# ESP32S31_RADIO register map
Vendor: Espressif; Series: ESP32-S31; File version: 3.52
Registers are 32-bit, read-write, no defined reset value unless marked. A register's access mark holds for its fields unless they carry their own. Offsets are from the block's base; [hi:lo] are bit positions; {n}, {i} and the like mark numbered series; <NAME> marks a mode.

## BLUETOOTH_SCHEDULER_INTERRUPT_RUNTIME — Two scheduler words transferred with BLUETOOTH_INTERRUPT_BANK to the primary hard handler. The complete source-124 suffix can read SCHEDULER_STATE at two distinct temporal points and can write a complete zero image to SCHEDULER_REFERENCE. Keeping this sparse physical view outside the task-side controller partition prevents either owner from manufacturing an MMIO alias.
Base 0x20101000
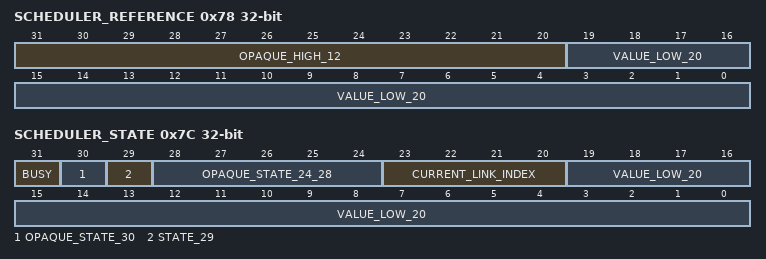
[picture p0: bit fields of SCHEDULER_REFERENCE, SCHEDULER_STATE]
0x78 SCHEDULER_REFERENCE — The source-124 handler can publish the complete zero image when bank-one source 3 observes an idle scheduler. Other scheduler users compare bits 0..19 or publish complete images; upper encoding remains unknown.
  [31:20] OPAQUE_HIGH_12, [19:0] VALUE_LOW_20
0x7C SCHEDULER_STATE — The source-124 handler reads this shared scheduler state at a bank-one reference gate and again before publishing deferred work. Its deferred-work predicate requires both STATE_29 and BUSY. The complete current-link-index leaf returns bits 23:20. Command transactions also wait while BUSY is set; other complete users consume or publish the low 20 and low 30 bits.
  [31] BUSY
  [30] OPAQUE_STATE_30
  [29] STATE_29 — Positional state sampled together with BUSY by the complete source-124 deferred-work predicate. Its independent hardware meaning remains unqualified.
  [28:24] OPAQUE_STATE_24_28
  [23:20] CURRENT_LINK_INDEX — Zero-based current scheduler hardware-list index returned by the complete current-link-index leaf.
  [19:0] VALUE_LOW_20

## BLUETOOTH_RESET_IDLE_STATUS_0 — One independently bounded Bluetooth baseband reset-idle status word. The complete bbmac_idle_for_swrst leaf proves the exact predicate but neither address adjacency nor the function name proves a wider physical block.
Base 0x20101550
Same registers: SHARED_BASEBAND_RESET_IDLE_STATUS 0x20103088
0x00 STATUS ro — bbmac_idle_for_swrst requires the observed low four-bit field to be zero before reporting idle.
  [3:0] LOW_4_UNKNOWN — The reset-idle predicate fails when this exact field is nonzero.

## SHARED_BASEBAND_TX_TIMING — One physical baseband timing word reached by the common BTBB initializer. The named vendor leaf carries a historical Zigbee prefix, but the current evidence proves only the exact shared initialization transaction and does not grant protocol-exclusive ownership.
Base 0x20102010
0x00 AUXILIARY_TX_ON_DELAY — The complete named setter replaces bits 16:26 with an encoded argument image and preserves every other bit.
  [26:16] ENCODED_IMAGE — The setter stores ((argument - 10) << 3) in this eleven-bit field; its low three bits therefore become zero.

## BTDM_SCHEDULER_TABLE — Sixteen-entry scheduler hardware-list table. Complete current insertion-begin, insertion-end and lifecycle bodies prove the finite entry count, 0x10-byte stride and low-20-bit compressed SRAM head. Same-chip public named header accessors independently establish the hardware-list role. The upper twelve bits and the unobserved words inside each stride remain unknown.
Base 0x2010B000
{0x0+0x10*i} ENTRY{i} (i=0..15) — Scheduler hardware-list entry. Bits 0..19 hold a compressed SRAM head and bits 20..31 remain unassigned.
  [19:0] HEAD_POINTER — Compressed four-byte-aligned 0x2f-prefixed SRAM hardware-list head. Zero denotes no published head.

## BTDM_LOW_POWER_CONFIG — Sparse low-power configuration/status words reached by complete BTDM runtime and btdm_sleep.c functions. Positional names preserve exact access direction and complete images without inventing clock, calibration or RTC semantics.
Base 0x20108800
0x00 STATUS_0000 ro — Complete word read by two BTDM sleep/runtime functions. Inner encoding remains unknown.
  [31:0] IMAGE
0x04 COMMAND_0004 wo — Complete functions publish dynamic complete images and the independently observed finite complete images 0x10, 0x20, 0x40 and 0x80. Whole-word authority remains a register-level fact.
0x08 COMMAND_0008 wo — Complete word receives runtime-derived images and the independently observed finite images 0x10, 0x20, 0x40 and 0x80.
  [31:0] IMAGE
{0x2C+4i} CONFIG{i} (i=0..7) — Eight complete configuration words initialized to the finite sequence 69, 17, 67, 18, 70, 17, 70, 15 and later consumed by BTDM runtime functions.
  [31:0] IMAGE
